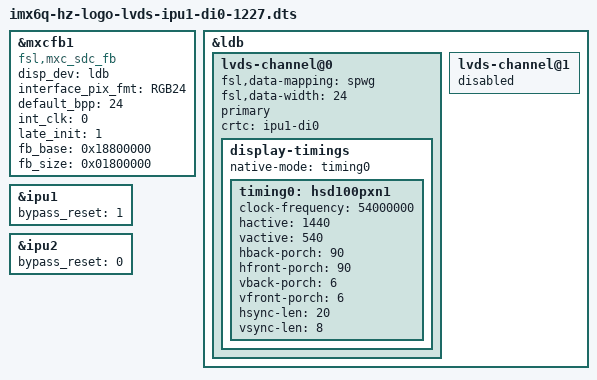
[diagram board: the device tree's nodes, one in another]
/*
 * Copyright (C) 2015 Freescale Semiconductor, Inc.
 *
 * This program is free software; you can redistribute it and/or modify
 * it under the terms of the GNU General Public License version 2 as
 * published by the Free Software Foundation.
 */

#include "imx6q-hz.dts"

&mxcfb1 {
	compatible = "fsl,mxc_sdc_fb";
	disp_dev = "ldb";
	interface_pix_fmt = "RGB24";
	default_bpp = <24>;
	int_clk = <0>;
	late_init = <1>;
	fb_base = <0x18800000>;  /* Frame buffer base address, it is same as CONFIG_FB_BASE in Uboot. */
	fb_size = <0x01800000>;  /* Reserved display memory size, bigger than 3 x framer buffer size. */
	status = "okay";
};

/*&ldb {
	split-mode;
	status = "okay";
	lvds-channel@0 {
        fsl,data-mapping = "spwg";
		/*fsl,data-mapping = "jeida";*/
/*        fsl,data-width = <24>;
		primary;
		crtc = "ipu1-di0";
		status = "okay";
		display-timings {
                        native-mode = <&timing0>;
                        timing0: hsd100pxn1 {
                                clock-frequency = <154752000>;
                                hactive = <1920>;
                                vactive = <1200>;
                                hback-porch = <40>;
                                hfront-porch = <100>;
                                vback-porch = <10>;
                                vfront-porch = <20>;
                                hsync-len = <20>;
                                vsync-len = <10>;

                        };

                };
	};

	lvds-channel@1 {
		status = "disabled";
	};
};*/
&ldb {
	
	status = "okay";
	lvds-channel@0 {
        fsl,data-mapping = "spwg";
		/*fsl,data-mapping = "jeida";*/
        fsl,data-width = <24>;
		primary;
		crtc = "ipu1-di0";
		status = "okay";
		display-timings {
                        native-mode = <&timing0>;
                        timing0: hsd100pxn1 {
                                clock-frequency = <54000000>;
                                hactive = <1440>;
                                vactive = <540>;
                                hback-porch = <90>;
                                hfront-porch = <90>;
                                vback-porch = <6>;
                                vfront-porch = <6>;
                                hsync-len = <20>;
                                vsync-len = <8>;

                        };

                };
	};

	lvds-channel@1 {
		status = "disabled";
	};
};

&ipu1 {
	bypass_reset = <1>;
	status = "okay";
};

&ipu2 {
	bypass_reset = <0>;
	status = "okay";
};



